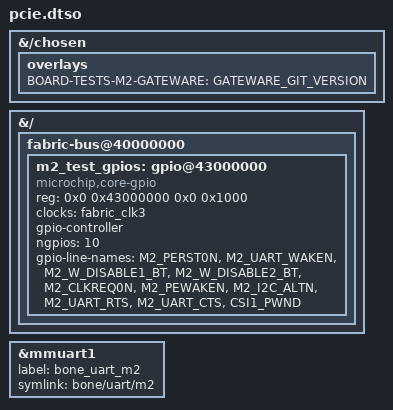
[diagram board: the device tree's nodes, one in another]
// SPDX-License-Identifier: (GPL-2.0 OR MIT)
/* Copyright (c) 2020-2021 Microchip Technology Inc */

/dts-v1/;
/plugin/;


&{/chosen} {
	overlays {
		BOARD-TESTS-M2-GATEWARE = "GATEWARE_GIT_VERSION";
	};
};

&{/} {
	fabric-bus@40000000 {
		m2_test_gpios: gpio@43000000 {
			compatible = "microchip,core-gpio";
			reg = <0x0 0x43000000 0x0 0x1000>;
			clocks = <&fabric_clk3>;
			gpio-controller;
			#gpio-cells = <2>;
			ngpios=<10>;
			status = "okay";
			gpio-line-names = "M2_PERST0N", "M2_UART_WAKEN", "M2_W_DISABLE1_BT", "M2_W_DISABLE2_BT",
			                  "M2_CLKREQ0N", "M2_PEWAKEN", "M2_I2C_ALTN", "M2_UART_RTS", "M2_UART_CTS","CSI1_PWND";
		};
	};
};

&mmuart1 {
	status = "okay";
	label = "bone_uart_m2";
	symlink = "bone/uart/m2";
};
